# BL616/BL618 register map
Vendor: Bouffalo Lab; File version: 1.0
Registers are 32-bit, read-write, reset 0x0 unless marked. A register's access mark holds for its fields unless they carry their own. Offsets are from the block's base; [hi:lo] are bit positions; {n}, {i} and the like mark numbered series; 'fields as' and 'values as' point back to an identical list.

## I2C[{n}] — Inter-Integrated Circuit bus
Base 0x2000A300; array of 2, step 0x600
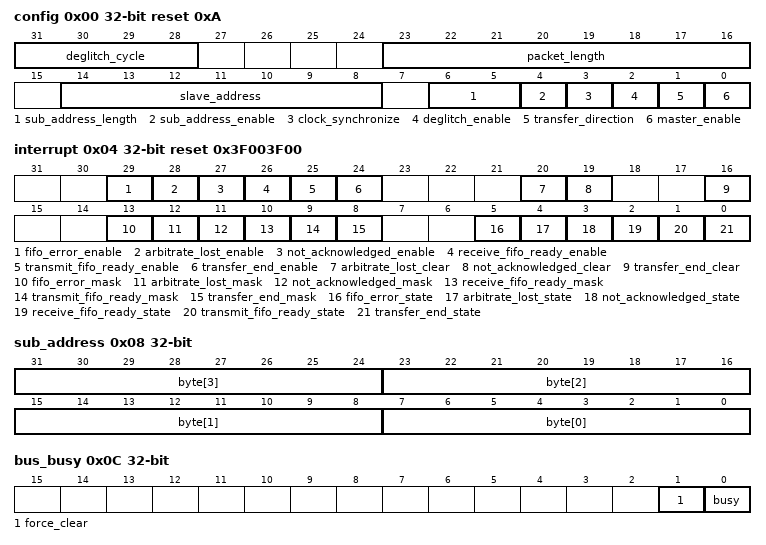
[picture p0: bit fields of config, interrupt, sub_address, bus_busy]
0x00 config reset 0xA — Function configuration register
  [31:28] deglitch_cycle — De-glitch function cycle count
  [23:16] packet_length — Byte count for each packet
  [14:8] slave_address — I2C transaction slave address
  [6:5] sub_address_length — Byte count for I2C sub-address
    0=one (Sub-addresses include 1 byte); 1=two (Sub-addresses include 2 bytes); 2=three (Sub-addresses include 3 bytes); 3=four (Sub-addresses include 4 bytes)
  [4] sub_address_enable — Enable sub-address fields
    1=Enable sub-address fields; 0=Disable sub-address fields
  [3] clock_synchronize — Enable I2C clock synchronization . Enable this bit to support multi-master and clock-stretching. It should not be turned-off normally.
    1=Enable clock synchronization; 0=Disable clock synchronization
  [2] deglitch_enable — Enable de-glitch function on all input pins
    1=Enable de-glitch function on inputs; 0=Disable de-glitch function on inputs
  [1] transfer_direction — Packet transfer direction
    0=Write from master side; 1=Read from master side
  [0] master_enable — Enable signal of I2C master function . Asserting this bit will trigger the transaction, and should be de-asserted after finish.
    1=Enable I2C master function; 0=Disable I2C master function
0x04 interrupt reset 0x3F003F00 — Interrupt enables, states and masks
  [29] fifo_error_enable — Transmit or receive FIFO error interrupt enable
    1=Enable interrupt; 0=Disable interrupt
  [28] arbitrate_lost_enable — Arbitration lost interrupt enable
    1=Enable interrupt; 0=Disable interrupt
  [27] not_acknowledged_enable — Not-acknowledged response interrupt enable
    1=Enable interrupt; 0=Disable interrupt
  [26] receive_fifo_ready_enable — Receive FIFO ready interrupt enable
    1=Enable interrupt; 0=Disable interrupt
  [25] transmit_fifo_ready_enable — Transmit FIFO ready interrupt enable
    1=Enable interrupt; 0=Disable interrupt
  [24] transfer_end_enable — Transfer ended interrupt enable
    1=Enable interrupt; 0=Disable interrupt
  [20] arbitrate_lost_clear wo — Write 1 to clear arbitration lost
    1=clear (Write 1 to clear interrupt state)
  [19] not_acknowledged_clear wo — Write 1 to clear not-acknowledged response
    1=clear (Write 1 to clear interrupt state)
  [16] transfer_end_clear wo — Write 1 to clear transfer ended
    1=clear (Write 1 to clear interrupt state)
  [13] fifo_error_mask — Transmit or receive FIFO error interrupt mask
    1=Mask interrupt; 0=Unmask interrupt
  [12] arbitrate_lost_mask — Arbitration lost interrupt mask
    1=Mask interrupt; 0=Unmask interrupt
  [11] not_acknowledged_mask — Not-acknowledged response interrupt mask
    1=Mask interrupt; 0=Unmask interrupt
  [10] receive_fifo_ready_mask — Receive FIFO ready interrupt mask
    1=Mask interrupt; 0=Unmask interrupt
  [9] transmit_fifo_ready_mask — Transmit FIFO ready interrupt mask
    1=Mask interrupt; 0=Unmask interrupt
  [8] transfer_end_mask — Transfer ended interrupt mask
    1=Mask interrupt; 0=Unmask interrupt
  [5] fifo_error_state ro — Transmit or receive FIFO error interrupt state . Auto cleared when FIFO overflow or underflow error flag is cleared.
    1=has_interrupt; 0=No interrupt occurred
  [4] arbitrate_lost_state ro — Arbitration lost interrupt state
    1=has_interrupt; 0=No interrupt occurred
  [3] not_acknowledged_state ro — Not-acknowledged response interrupt state
    1=has_interrupt; 0=No interrupt occurred
  [2] receive_fifo_ready_state ro — Receive FIFO ready interrupt state . Auto cleared when data is popped from receive FIFO.
    1=has_interrupt; 0=No interrupt occurred
  [1] transmit_fifo_ready_state ro — Transmit FIFO ready interrupt state . Auto cleared when data is pushed into transmit FIFO.
    1=has_interrupt; 0=No interrupt occurred
  [0] transfer_end_state ro — Transfer ended interrupt state
    1=has_interrupt; 0=No interrupt occurred
0x08 sub_address — Register address of slave device
  [8n+7:8n] byte[{n}] (n=0..3) — I2C sub-address byte {n}
0x0C bus_busy — Bus busy state indicator
  [1] force_clear wo — Force clear I2C bus busy state . Not for normal use; only use when I2C bus hangs
    1=clear (Write 1 to force clear busy flag)
  [0] busy ro — Indicator to I2C bus busy signal
    1=busy (Bus is busy); 0=idle (Bus is not busy)
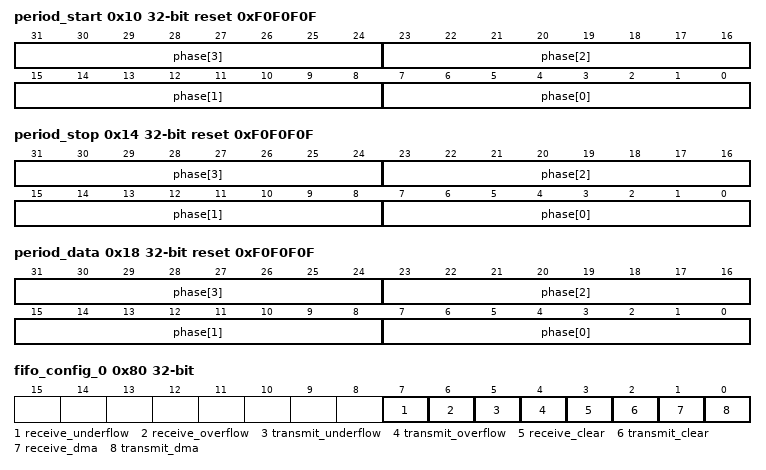
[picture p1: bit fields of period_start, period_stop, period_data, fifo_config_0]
0x10 period_start reset 0xF0F0F0F — Duration of start phase
  [8n+7:8n] phase[{n}] (n=0..3) — Length of start condition phase {n}
0x14 period_stop reset 0xF0F0F0F — Duration of stop phase
  [8n+7:8n] phase[{n}] (n=0..3) — Length of stop condition phase {n}
0x18 period_data reset 0xF0F0F0F — Duration of data phase
  [8n+7:8n] phase[{n}] (n=0..3) — Length of data condition phase {n}
0x80 fifo_config_0 — FIFO configuration register 0
  [7] receive_underflow ro — Receive FIFO underflow flag . Can be cleared using `receive_clear`.
    0=not_underflow (No FIFO buffer underflow); 1=underflow (Has FIFO buffer underflow)
  [6] receive_overflow ro — Receive FIFO overflow flag . Can be cleared using `receive_clear`.
    0=not_overflow (No FIFO buffer overflow); 1=overflow (Has FIFO buffer overflow)
  [5] transmit_underflow ro — Transmit FIFO underflow flag . Can be cleared using `transmit_clear`.
    values as receive_underflow
  [4] transmit_overflow ro — Transmit FIFO overflow flag . Can be cleared using `transmit_clear`.
    values as receive_overflow
  [3] receive_clear wo — Clears receive FIFO overflow and underflow flags
    1=clear (Write 1 to clear fifo flags)
  [2] transmit_clear wo — Clears transmit FIFO overflow and underflow flags
    1=clear (Write 1 to clear fifo flags)
  [1] receive_dma — Enable signal of receive DMA interface
    1=Enable DMA interface; 0=Disable DMA interface
  [0] transmit_dma — Enable signal of transmit DMA interface
    1=Enable DMA interface; 0=Disable DMA interface
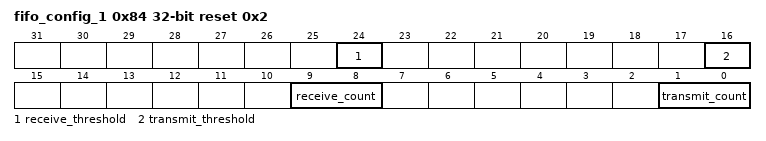
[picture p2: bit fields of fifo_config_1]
0x84 fifo_config_1 reset 0x2 — FIFO configuration register 1
  [24] receive_threshold — Receive FIFO threshold . DMA request will not be asserted if `receive_available` is less than this value
  [16] transmit_threshold — Transmit FIFO threshold . DMA request will not be asserted if `transmit_available` is less than this value
  [9:8] receive_count ro — Count of available data in receive FIFO
  [1:0] transmit_count ro — Count of available data in transmit FIFO
0x88 data_write wo — FIFO write data register
  [7:0] value — Write data to FIFO
0x8C data_read ro — FIFO read data register
  [7:0] value — Read data from FIFO
